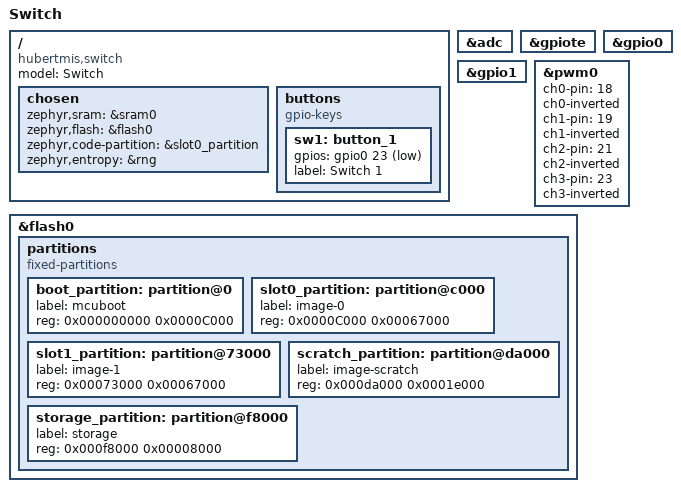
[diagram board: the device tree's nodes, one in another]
/*
 * Copyright (c) 2022 Hubert Miś
 *
 * SPDX-License-Identifier: Apache-2.0
 */

/dts-v1/;
#include <nordic/nrf52840_qiaa.dtsi>

/ {
	model = "Switch";
	compatible = "hubertmis,switch";

	chosen {
		zephyr,sram = &sram0;
		zephyr,flash = &flash0;
		zephyr,code-partition = &slot0_partition;
	};

    buttons {
        compatible = "gpio-keys";
        sw1: button_1 {
            gpios = <&gpio0 23 (GPIO_PULL_UP | GPIO_ACTIVE_LOW)>;
            label = "Switch 1";
        };
    };

    /*
    * In some default configurations within the nRF Connect SDK,
    * e.g. on nRF52840, the chosen zephyr,entropy node is &cryptocell.
    * This devicetree overlay ensures that default is overridden wherever it
    * is set, as this application uses the RNG node for entropy exclusively.
    */
    chosen {
        zephyr,entropy = &rng;
    };

    /* These aliases are provided for compatibility with samples */
};

&adc {
	status = "okay";
};

&gpiote {
	status = "okay";
};

&gpio0 {
	status = "okay";
};

&gpio1 {
	status = "okay";
};

&pwm0 {
    status = "okay";
    ch0-pin = <18>;
    ch0-inverted;
    ch1-pin = <19>;
    ch1-inverted;
    ch2-pin = <21>;
    ch2-inverted;
    ch3-pin = <23>;
    ch3-inverted;
};

&flash0 {

	partitions {
		compatible = "fixed-partitions";
		#address-cells = <1>;
		#size-cells = <1>;

		boot_partition: partition@0 {
			label = "mcuboot";
			reg = <0x000000000 0x0000C000>;
		};
		slot0_partition: partition@c000 {
			label = "image-0";
			reg = <0x0000C000 0x00067000>;
		};
		slot1_partition: partition@73000 {
			label = "image-1";
			reg = <0x00073000 0x00067000>;
		};
		scratch_partition: partition@da000 {
			label = "image-scratch";
			reg = <0x000da000 0x0001e000>;
		};

		/*
		 * The flash starting at 0x000f8000 and ending at
		 * 0x000fffff is reserved for use by the application.
		 */

		/*
		 * Storage partition will be used by FCB/LittleFS/NVS
		 * if enabled.
		 */
		storage_partition: partition@f8000 {
			label = "storage";
			reg = <0x000f8000 0x00008000>;
		};
	};
};
